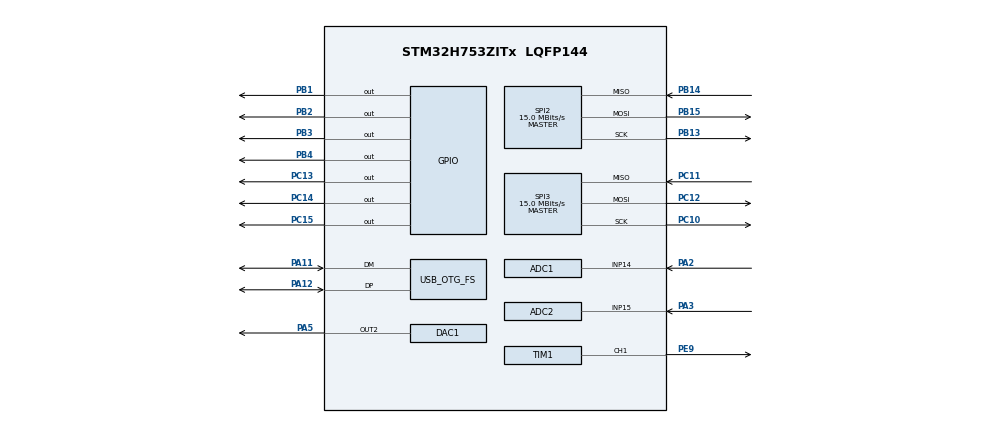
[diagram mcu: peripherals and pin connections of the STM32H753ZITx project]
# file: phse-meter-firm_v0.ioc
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ADC1.Channel-0\#ChannelRegularConversion=ADC_CHANNEL_14
ADC1.ConversionDataManagement=ADC_CONVERSIONDATA_DMA_CIRCULAR
ADC1.ExternalTrigConv=ADC_EXTERNALTRIG_T1_TRGO
ADC1.Mode=ADC_DUALMODE_REGSIMULT
ADC1.NbrOfConversionFlag=1
ADC1.OffsetNumber-0\#ChannelRegularConversion=ADC_OFFSET_NONE
ADC1.OffsetSignedSaturation-0\#ChannelRegularConversion=DISABLE
ADC1.Rank-0\#ChannelRegularConversion=1
ADC1.Resolution=ADC_RESOLUTION_16B
ADC1.SamplingTime-0\#ChannelRegularConversion=ADC_SAMPLETIME_8CYCLES_5
ADC1.master=1
ADC2.Channel-0\#ChannelRegularConversion=ADC_CHANNEL_15
ADC2.ClockPrescaler=ADC_CLOCK_ASYNC_DIV1
ADC2.Mode=ADC_DUALMODE_REGSIMULT
ADC2.NbrOfConversionFlag=1
ADC2.OffsetNumber-0\#ChannelRegularConversion=ADC_OFFSET_NONE
ADC2.OffsetSignedSaturation-0\#ChannelRegularConversion=DISABLE
ADC2.Rank-0\#ChannelRegularConversion=1
ADC2.Resolution=ADC_RESOLUTION_16B
ADC2.SamplingTime-0\#ChannelRegularConversion=ADC_SAMPLETIME_8CYCLES_5
CORTEX_M7.CPU_DCache=Disabled
CORTEX_M7.CPU_ICache=Disabled
CORTEX_M7.MPU_Control=__NULL
CORTEX_M7.default_mode_Activation=1
DAC1.DAC_Channel-DAC_OUT2=DAC_CHANNEL_2
Dma.ADC1.0.Direction=DMA_PERIPH_TO_MEMORY
Dma.ADC1.0.EventEnable=DISABLE
Dma.ADC1.0.FIFOMode=DMA_FIFOMODE_DISABLE
Dma.ADC1.0.Instance=DMA1_Stream0
Dma.ADC1.0.MemDataAlignment=DMA_MDATAALIGN_WORD
Dma.ADC1.0.MemInc=DMA_MINC_ENABLE
Dma.ADC1.0.Mode=DMA_CIRCULAR
Dma.ADC1.0.PeriphDataAlignment=DMA_PDATAALIGN_WORD
Dma.ADC1.0.PeriphInc=DMA_PINC_DISABLE
Dma.ADC1.0.Polarity=HAL_DMAMUX_REQ_GEN_RISING
Dma.ADC1.0.Priority=DMA_PRIORITY_LOW
Dma.ADC1.0.RequestNumber=1
Dma.ADC1.0.SignalID=NONE
Dma.ADC1.0.SyncEnable=DISABLE
Dma.ADC1.0.SyncPolarity=HAL_DMAMUX_SYNC_NO_EVENT
Dma.ADC1.0.SyncRequestNumber=1
Dma.ADC1.0.SyncSignalID=NONE
Dma.Request0=ADC1
Mcu.Family=STM32H7
Mcu.Name=STM32H753ZITx
Mcu.Package=LQFP144
NUCLEO-H753ZI.VCP=true
NVIC.DMA1_Stream0_IRQn=true\:0\:0\:false\:false\:true\:false\:true\:true
NVIC.OTG_FS_IRQn=true\:0\:0\:false\:false\:true\:false\:true\:true
NVIC.PriorityGroup=NVIC_PRIORITYGROUP_4
NVIC.TIM6_DAC_IRQn=true\:0\:0\:false\:false\:true\:true\:true\:true
PA11.Mode=Device_Only
PA11.Signal=USB_OTG_FS_DM
PA12.Mode=Device_Only
PA12.Signal=USB_OTG_FS_DP
PA2.Signal=ADCx_INP14
PA3.Signal=ADCx_INP15
PA5.Signal=COMP_DAC12_group
PB1.Signal=GPIO_Output
PB13.Mode=Full_Duplex_Master
PB13.Signal=SPI2_SCK
PB14.Mode=Full_Duplex_Master
PB14.Signal=SPI2_MISO
PB15.Mode=Full_Duplex_Master
PB15.Signal=SPI2_MOSI
PB2.Signal=GPIO_Output
PB3\ (JTDO/TRACESWO).Signal=GPIO_Output
PB4\ (NJTRST).Signal=GPIO_Output
PC10.Mode=Full_Duplex_Master
PC10.Signal=SPI3_SCK
PC11.Mode=Full_Duplex_Master
PC11.Signal=SPI3_MISO
PC12.Mode=Full_Duplex_Master
PC12.Signal=SPI3_MOSI
PC13.Signal=GPIO_Output
PC14-OSC32_IN\ (OSC32_IN).Signal=GPIO_Output
PC15-OSC32_OUT\ (OSC32_OUT).Signal=GPIO_Output
PD8.Signal=USART3_TX
PD9.Signal=USART3_RX
PE7.Signal=S_TIM1_ETR
PE9.Signal=S_TIM1_CH1
PH0-OSC_IN\ (PH0).Mode=HSE-External-Oscillator
PH0-OSC_IN\ (PH0).Signal=RCC_OSC_IN
PH1-OSC_OUT\ (PH1).Mode=HSE-External-Oscillator
PH1-OSC_OUT\ (PH1).Signal=RCC_OSC_OUT
ProjectManager.HeapSize=0x200
ProjectManager.StackSize=0x400
ProjectManager.TargetToolchain=STM32CubeIDE
RCC.ADCFreq_Value=50000000
RCC.APB1Freq_Value=120000000
RCC.APB2Freq_Value=120000000
RCC.APB3Freq_Value=120000000
RCC.APB4Freq_Value=120000000
RCC.CortexFreq_Value=480000000
RCC.D1PPRE=RCC_APB3_DIV2
RCC.D2PPRE1=RCC_APB1_DIV2
RCC.D2PPRE2=RCC_APB2_DIV2
RCC.D3PPRE=RCC_APB4_DIV2
RCC.DIVM1=2
RCC.DIVM2=2
RCC.DIVN1=240
RCC.DIVN2=50
RCC.DIVP2=4
RCC.DIVQ1=8
RCC.HCLKFreq_Value=240000000
RCC.HPRE=RCC_HCLK_DIV2
RCC.HSE_VALUE=8000000
RCC.PLL2FRACN=0
RCC.PLLFRACN=0
RCC.PLLSourceVirtual=RCC_PLLSOURCE_HSE
RCC.PWR_Regulator_Voltage_Scale=PWR_REGULATOR_VOLTAGE_SCALE0
RCC.SYSCLKFreq_VALUE=480000000
RCC.SYSCLKSource=RCC_SYSCLKSOURCE_PLLCLK
RCC.USBCLockSelection=RCC_USBCLKSOURCE_HSI48
RCC.USBFreq_Value=48000000
SH.ADCx_INP14.0=ADC1_INP14,IN14-Single-Ended
SH.ADCx_INP15.0=ADC2_INP15,IN15-Single-Ended
SH.COMP_DAC12_group.0=DAC1_OUT2,DAC_OUT2
SH.S_TIM1_CH1.0=TIM1_CH1,PWM Generation1 CH1
SH.S_TIM1_ETR.0=TIM1_ETR
SPI2.BaudRatePrescaler=SPI_BAUDRATEPRESCALER_8
SPI2.CalculateBaudRate=15.0 MBits/s
SPI2.DataSize=SPI_DATASIZE_8BIT
SPI2.Direction=SPI_DIRECTION_2LINES
SPI2.FirstBit=SPI_FIRSTBIT_LSB
SPI2.Mode=SPI_MODE_MASTER
SPI2.VirtualType=VM_MASTER
SPI3.BaudRatePrescaler=SPI_BAUDRATEPRESCALER_8
SPI3.CalculateBaudRate=15.0 MBits/s
SPI3.DataSize=SPI_DATASIZE_8BIT
SPI3.Direction=SPI_DIRECTION_2LINES
SPI3.FirstBit=SPI_FIRSTBIT_LSB
SPI3.Mode=SPI_MODE_MASTER
SPI3.VirtualType=VM_MASTER
TIM1.Channel-PWM\ Generation1\ CH1=TIM_CHANNEL_1
TIM1.Period=240-1
TIM1.Pulse-PWM\ Generation1\ CH1=120
TIM1.TIM_MasterOutputTrigger=TIM_TRGO_UPDATE
TIM6.Period=1000-1
TIM6.Prescaler=2400-1
USB_DEVICE.CLASS_NAME_FS=CDC
USB_DEVICE.VirtualMode-CDC_FS=Cdc
USB_DEVICE.VirtualModeFS=Cdc_FS
USB_OTG_FS.VirtualMode=Device_Only
VP_MEMORYMAP_VS_MEMORYMAP.Mode=CurAppReg
VP_NUCLEO-H753ZI_VS_BSP_COMMON.Mode=COMMON
VP_TIM1_VS_ClockSourceINT.Mode=Internal
VP_TIM6_VS_ClockSourceINT.Mode=Enable_Timer
VP_USB_DEVICE_VS_USB_DEVICE_CDC_FS.Mode=CDC_FS
board=NUCLEO-H753ZI

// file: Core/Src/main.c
/* USER CODE BEGIN Header */
/**
  ******************************************************************************
  * @file           : main.c
  * @brief          : Main program body
  ******************************************************************************
  * @attention
  *
  * Copyright (c) 2026 STMicroelectronics.
  * All rights reserved.
  *
  * This software is licensed under terms that can be found in the LICENSE file
  * in the root directory of this software component.
  * If no LICENSE file comes with this software, it is provided AS-IS.
  *
  ******************************************************************************
  */
/* USER CODE END Header */
#include "main.h"
#include "usb_device.h"

/* USER CODE BEGIN Includes */
#include "functions.h"
/* USER CODE END Includes */

COM_InitTypeDef BspCOMInit;
ADC_HandleTypeDef hadc1;
ADC_HandleTypeDef hadc2;
DMA_HandleTypeDef hdma_adc1;

DAC_HandleTypeDef hdac1;

SPI_HandleTypeDef hspi2;
SPI_HandleTypeDef hspi3;

TIM_HandleTypeDef htim1;
TIM_HandleTypeDef htim6;

void SystemClock_Config(void);
void PeriphCommonClock_Config(void);
static void MX_GPIO_Init(void);
static void MX_DMA_Init(void);
static void MX_ADC1_Init(void);
static void MX_ADC2_Init(void);
static void MX_TIM1_Init(void);
static void MX_TIM6_Init(void);
static void MX_SPI2_Init(void);
static void MX_SPI3_Init(void);
static void MX_DAC1_Init(void);

int main(void)
{

  /* MCU Configuration--------------------------------------------------------*/

  /* Reset of all peripherals, Initializes the Flash interface and the Systick. */
  HAL_Init();

  /* Configure the system clock */
  SystemClock_Config();

  /* Configure the peripherals common clocks */
  PeriphCommonClock_Config();

  /* Initialize all configured peripherals */
  MX_GPIO_Init();
  MX_DMA_Init();
  MX_ADC1_Init();
  MX_ADC2_Init();
  MX_USB_DEVICE_Init();
  MX_TIM1_Init();
  MX_TIM6_Init();
  MX_SPI2_Init();
  MX_SPI3_Init();
  MX_DAC1_Init();
  /* USER CODE BEGIN 2 */
  StartUp();      /* clocks, params, ADC multimode/calib, TIM1 trigger */
  Start_Main();   /* enable the 100 Hz TIM6 tick                       */
  /* USER CODE END 2 */

  /* Initialize COM1 port (115200, 8 bits (7-bit data + 1 stop bit), no parity */
  BspCOMInit.BaudRate   = 115200;
  BspCOMInit.WordLength = COM_WORDLENGTH_8B;
  BspCOMInit.StopBits   = COM_STOPBITS_1;
  BspCOMInit.Parity     = COM_PARITY_NONE;
  BspCOMInit.HwFlowCtl  = COM_HWCONTROL_NONE;
  if (BSP_COM_Init(COM1, &BspCOMInit) != BSP_ERROR_NONE)
  {
    Error_Handler();
  }

  /* Infinite loop */
  while (1)
  {

    /* USER CODE BEGIN 3 */
    Main_Processing();
  }
  /* USER CODE END 3 */
}

void SystemClock_Config(void)
{
  RCC_OscInitTypeDef RCC_OscInitStruct = {0};
  RCC_ClkInitTypeDef RCC_ClkInitStruct = {0};

  /** Supply configuration update enable
  */
  HAL_PWREx_ConfigSupply(PWR_LDO_SUPPLY);

  /** Configure the main internal regulator output voltage
  */
  __HAL_PWR_VOLTAGESCALING_CONFIG(PWR_REGULATOR_VOLTAGE_SCALE0);

  while(!__HAL_PWR_GET_FLAG(PWR_FLAG_VOSRDY)) {}

  /** Initializes the RCC Oscillators according to the specified parameters
  * in the RCC_OscInitTypeDef structure.
  */
  RCC_OscInitStruct.OscillatorType = RCC_OSCILLATORTYPE_HSI48|RCC_OSCILLATORTYPE_HSE;
  RCC_OscInitStruct.HSEState = RCC_HSE_ON;
  RCC_OscInitStruct.HSI48State = RCC_HSI48_ON;
  RCC_OscInitStruct.PLL.PLLState = RCC_PLL_ON;
  RCC_OscInitStruct.PLL.PLLSource = RCC_PLLSOURCE_HSE;
  RCC_OscInitStruct.PLL.PLLM = 2;
  RCC_OscInitStruct.PLL.PLLN = 240;
  RCC_OscInitStruct.PLL.PLLP = 2;
  RCC_OscInitStruct.PLL.PLLQ = 8;
  RCC_OscInitStruct.PLL.PLLR = 2;
  RCC_OscInitStruct.PLL.PLLRGE = RCC_PLL1VCIRANGE_2;
  RCC_OscInitStruct.PLL.PLLVCOSEL = RCC_PLL1VCOWIDE;
  RCC_OscInitStruct.PLL.PLLFRACN = 0;
  if (HAL_RCC_OscConfig(&RCC_OscInitStruct) != HAL_OK)
  {
    Error_Handler();
  }

  /** Initializes the CPU, AHB and APB buses clocks
  */
  RCC_ClkInitStruct.ClockType = RCC_CLOCKTYPE_HCLK|RCC_CLOCKTYPE_SYSCLK
                              |RCC_CLOCKTYPE_PCLK1|RCC_CLOCKTYPE_PCLK2
                              |RCC_CLOCKTYPE_D3PCLK1|RCC_CLOCKTYPE_D1PCLK1;
  RCC_ClkInitStruct.SYSCLKSource = RCC_SYSCLKSOURCE_PLLCLK;
  RCC_ClkInitStruct.SYSCLKDivider = RCC_SYSCLK_DIV1;
  RCC_ClkInitStruct.AHBCLKDivider = RCC_HCLK_DIV2;
  RCC_ClkInitStruct.APB3CLKDivider = RCC_APB3_DIV2;
  RCC_ClkInitStruct.APB1CLKDivider = RCC_APB1_DIV2;
  RCC_ClkInitStruct.APB2CLKDivider = RCC_APB2_DIV2;
  RCC_ClkInitStruct.APB4CLKDivider = RCC_APB4_DIV2;

  if (HAL_RCC_ClockConfig(&RCC_ClkInitStruct, FLASH_LATENCY_4) != HAL_OK)
  {
    Error_Handler();
  }
}

void PeriphCommonClock_Config(void)
{
  RCC_PeriphCLKInitTypeDef PeriphClkInitStruct = {0};

  /** Initializes the peripherals clock
  */
  PeriphClkInitStruct.PeriphClockSelection = RCC_PERIPHCLK_ADC;
  PeriphClkInitStruct.PLL2.PLL2M = 2;
  PeriphClkInitStruct.PLL2.PLL2N = 50;
  PeriphClkInitStruct.PLL2.PLL2P = 4;
  PeriphClkInitStruct.PLL2.PLL2Q = 2;
  PeriphClkInitStruct.PLL2.PLL2R = 2;
  PeriphClkInitStruct.PLL2.PLL2RGE = RCC_PLL2VCIRANGE_2;
  PeriphClkInitStruct.PLL2.PLL2VCOSEL = RCC_PLL2VCOWIDE;
  PeriphClkInitStruct.PLL2.PLL2FRACN = 0;
  PeriphClkInitStruct.AdcClockSelection = RCC_ADCCLKSOURCE_PLL2;
  if (HAL_RCCEx_PeriphCLKConfig(&PeriphClkInitStruct) != HAL_OK)
  {
    Error_Handler();
  }
}

static void MX_ADC1_Init(void)
{

  ADC_MultiModeTypeDef multimode = {0};
  ADC_ChannelConfTypeDef sConfig = {0};

  /** Common config
  */
  hadc1.Instance = ADC1;
  hadc1.Init.ClockPrescaler = ADC_CLOCK_ASYNC_DIV1;
  hadc1.Init.Resolution = ADC_RESOLUTION_16B;
  hadc1.Init.ScanConvMode = ADC_SCAN_DISABLE;
  hadc1.Init.EOCSelection = ADC_EOC_SINGLE_CONV;
  hadc1.Init.LowPowerAutoWait = DISABLE;
  hadc1.Init.ContinuousConvMode = DISABLE;
  hadc1.Init.NbrOfConversion = 1;
  hadc1.Init.DiscontinuousConvMode = DISABLE;
  hadc1.Init.ExternalTrigConv = ADC_EXTERNALTRIG_T1_TRGO;
  hadc1.Init.ExternalTrigConvEdge = ADC_EXTERNALTRIGCONVEDGE_RISING;
  hadc1.Init.ConversionDataManagement = ADC_CONVERSIONDATA_DMA_CIRCULAR;
  hadc1.Init.Overrun = ADC_OVR_DATA_PRESERVED;
  hadc1.Init.LeftBitShift = ADC_LEFTBITSHIFT_NONE;
  hadc1.Init.OversamplingMode = DISABLE;
  hadc1.Init.Oversampling.Ratio = 1;
  if (HAL_ADC_Init(&hadc1) != HAL_OK)
  {
    Error_Handler();
  }

  /** Configure the ADC multi-mode
  */
  multimode.Mode = ADC_DUALMODE_REGSIMULT;
  multimode.DualModeData = ADC_DUALMODEDATAFORMAT_DISABLED;
  multimode.TwoSamplingDelay = ADC_TWOSAMPLINGDELAY_1CYCLE;
  if (HAL_ADCEx_MultiModeConfigChannel(&hadc1, &multimode) != HAL_OK)
  {
    Error_Handler();
  }

  /** Configure Regular Channel
  */
  sConfig.Channel = ADC_CHANNEL_14;
  sConfig.Rank = ADC_REGULAR_RANK_1;
  sConfig.SamplingTime = ADC_SAMPLETIME_8CYCLES_5;
  sConfig.SingleDiff = ADC_SINGLE_ENDED;
  sConfig.OffsetNumber = ADC_OFFSET_NONE;
  sConfig.Offset = 0;
  sConfig.OffsetSignedSaturation = DISABLE;
  if (HAL_ADC_ConfigChannel(&hadc1, &sConfig) != HAL_OK)
  {
    Error_Handler();
  }

}

static void MX_ADC2_Init(void)
{

  ADC_ChannelConfTypeDef sConfig = {0};

  /** Common config
  */
  hadc2.Instance = ADC2;
  hadc2.Init.ClockPrescaler = ADC_CLOCK_ASYNC_DIV1;
  hadc2.Init.Resolution = ADC_RESOLUTION_16B;
  hadc2.Init.ScanConvMode = ADC_SCAN_DISABLE;
  hadc2.Init.EOCSelection = ADC_EOC_SINGLE_CONV;
  hadc2.Init.LowPowerAutoWait = DISABLE;
  hadc2.Init.ContinuousConvMode = DISABLE;
  hadc2.Init.NbrOfConversion = 1;
  hadc2.Init.DiscontinuousConvMode = DISABLE;
  hadc2.Init.ConversionDataManagement = ADC_CONVERSIONDATA_DR;
  hadc2.Init.Overrun = ADC_OVR_DATA_PRESERVED;
  hadc2.Init.LeftBitShift = ADC_LEFTBITSHIFT_NONE;
  hadc2.Init.OversamplingMode = DISABLE;
  hadc2.Init.Oversampling.Ratio = 1;
  if (HAL_ADC_Init(&hadc2) != HAL_OK)
  {
    Error_Handler();
  }

  /** Configure Regular Channel
  */
  sConfig.Channel = ADC_CHANNEL_15;
  sConfig.Rank = ADC_REGULAR_RANK_1;
  sConfig.SamplingTime = ADC_SAMPLETIME_8CYCLES_5;
  sConfig.SingleDiff = ADC_SINGLE_ENDED;
  sConfig.OffsetNumber = ADC_OFFSET_NONE;
  sConfig.Offset = 0;
  sConfig.OffsetSignedSaturation = DISABLE;
  if (HAL_ADC_ConfigChannel(&hadc2, &sConfig) != HAL_OK)
  {
    Error_Handler();
  }

}

static void MX_DAC1_Init(void)
{

  DAC_ChannelConfTypeDef sConfig = {0};

  /** DAC Initialization
  */
  hdac1.Instance = DAC1;
  if (HAL_DAC_Init(&hdac1) != HAL_OK)
  {
    Error_Handler();
  }

  /** DAC channel OUT2 config
  */
  sConfig.DAC_SampleAndHold = DAC_SAMPLEANDHOLD_DISABLE;
  sConfig.DAC_Trigger = DAC_TRIGGER_NONE;
  sConfig.DAC_OutputBuffer = DAC_OUTPUTBUFFER_ENABLE;
  sConfig.DAC_ConnectOnChipPeripheral = DAC_CHIPCONNECT_DISABLE;
  sConfig.DAC_UserTrimming = DAC_TRIMMING_FACTORY;
  if (HAL_DAC_ConfigChannel(&hdac1, &sConfig, DAC_CHANNEL_2) != HAL_OK)
  {
    Error_Handler();
  }

}

static void MX_SPI2_Init(void)
{

  /* SPI2 parameter configuration*/
  hspi2.Instance = SPI2;
  hspi2.Init.Mode = SPI_MODE_MASTER;
  hspi2.Init.Direction = SPI_DIRECTION_2LINES;
  hspi2.Init.DataSize = SPI_DATASIZE_8BIT;
  hspi2.Init.CLKPolarity = SPI_POLARITY_LOW;
  hspi2.Init.CLKPhase = SPI_PHASE_1EDGE;
  hspi2.Init.NSS = SPI_NSS_SOFT;
  hspi2.Init.BaudRatePrescaler = SPI_BAUDRATEPRESCALER_8;
  hspi2.Init.FirstBit = SPI_FIRSTBIT_LSB;
  hspi2.Init.TIMode = SPI_TIMODE_DISABLE;
  hspi2.Init.CRCCalculation = SPI_CRCCALCULATION_DISABLE;
  hspi2.Init.CRCPolynomial = 0x0;
  hspi2.Init.NSSPMode = SPI_NSS_PULSE_ENABLE;
  hspi2.Init.NSSPolarity = SPI_NSS_POLARITY_LOW;
  hspi2.Init.FifoThreshold = SPI_FIFO_THRESHOLD_01DATA;
  hspi2.Init.TxCRCInitializationPattern = SPI_CRC_INITIALIZATION_ALL_ZERO_PATTERN;
  hspi2.Init.RxCRCInitializationPattern = SPI_CRC_INITIALIZATION_ALL_ZERO_PATTERN;
  hspi2.Init.MasterSSIdleness = SPI_MASTER_SS_IDLENESS_00CYCLE;
  hspi2.Init.MasterInterDataIdleness = SPI_MASTER_INTERDATA_IDLENESS_00CYCLE;
  hspi2.Init.MasterReceiverAutoSusp = SPI_MASTER_RX_AUTOSUSP_DISABLE;
  hspi2.Init.MasterKeepIOState = SPI_MASTER_KEEP_IO_STATE_DISABLE;
  hspi2.Init.IOSwap = SPI_IO_SWAP_DISABLE;
  if (HAL_SPI_Init(&hspi2) != HAL_OK)
  {
    Error_Handler();
  }

}

static void MX_SPI3_Init(void)
{

  /* SPI3 parameter configuration*/
  hspi3.Instance = SPI3;
  hspi3.Init.Mode = SPI_MODE_MASTER;
  hspi3.Init.Direction = SPI_DIRECTION_2LINES;
  hspi3.Init.DataSize = SPI_DATASIZE_8BIT;
  hspi3.Init.CLKPolarity = SPI_POLARITY_LOW;
  hspi3.Init.CLKPhase = SPI_PHASE_1EDGE;
  hspi3.Init.NSS = SPI_NSS_SOFT;
  hspi3.Init.BaudRatePrescaler = SPI_BAUDRATEPRESCALER_8;
  hspi3.Init.FirstBit = SPI_FIRSTBIT_LSB;
  hspi3.Init.TIMode = SPI_TIMODE_DISABLE;
  hspi3.Init.CRCCalculation = SPI_CRCCALCULATION_DISABLE;
  hspi3.Init.CRCPolynomial = 0x0;
  hspi3.Init.NSSPMode = SPI_NSS_PULSE_ENABLE;
  hspi3.Init.NSSPolarity = SPI_NSS_POLARITY_LOW;
  hspi3.Init.FifoThreshold = SPI_FIFO_THRESHOLD_01DATA;
  hspi3.Init.TxCRCInitializationPattern = SPI_CRC_INITIALIZATION_ALL_ZERO_PATTERN;
  hspi3.Init.RxCRCInitializationPattern = SPI_CRC_INITIALIZATION_ALL_ZERO_PATTERN;
  hspi3.Init.MasterSSIdleness = SPI_MASTER_SS_IDLENESS_00CYCLE;
  hspi3.Init.MasterInterDataIdleness = SPI_MASTER_INTERDATA_IDLENESS_00CYCLE;
  hspi3.Init.MasterReceiverAutoSusp = SPI_MASTER_RX_AUTOSUSP_DISABLE;
  hspi3.Init.MasterKeepIOState = SPI_MASTER_KEEP_IO_STATE_DISABLE;
  hspi3.Init.IOSwap = SPI_IO_SWAP_DISABLE;
  if (HAL_SPI_Init(&hspi3) != HAL_OK)
  {
    Error_Handler();
  }

}

static void MX_TIM1_Init(void)
{

  TIM_ClockConfigTypeDef sClockSourceConfig = {0};
  TIM_MasterConfigTypeDef sMasterConfig = {0};
  TIM_OC_InitTypeDef sConfigOC = {0};
  TIM_BreakDeadTimeConfigTypeDef sBreakDeadTimeConfig = {0};

  htim1.Instance = TIM1;
  htim1.Init.Prescaler = 0;
  htim1.Init.CounterMode = TIM_COUNTERMODE_UP;
  htim1.Init.Period = 240-1;
  htim1.Init.ClockDivision = TIM_CLOCKDIVISION_DIV1;
  htim1.Init.RepetitionCounter = 0;
  htim1.Init.AutoReloadPreload = TIM_AUTORELOAD_PRELOAD_DISABLE;
  if (HAL_TIM_Base_Init(&htim1) != HAL_OK)
  {
    Error_Handler();
  }
  sClockSourceConfig.ClockSource = TIM_CLOCKSOURCE_INTERNAL;
  if (HAL_TIM_ConfigClockSource(&htim1, &sClockSourceConfig) != HAL_OK)
  {
    Error_Handler();
  }
  if (HAL_TIM_PWM_Init(&htim1) != HAL_OK)
  {
    Error_Handler();
  }
  sMasterConfig.MasterOutputTrigger = TIM_TRGO_UPDATE;
  sMasterConfig.MasterOutputTrigger2 = TIM_TRGO2_RESET;
  sMasterConfig.MasterSlaveMode = TIM_MASTERSLAVEMODE_DISABLE;
  if (HAL_TIMEx_MasterConfigSynchronization(&htim1, &sMasterConfig) != HAL_OK)
  {
    Error_Handler();
  }
  sConfigOC.OCMode = TIM_OCMODE_PWM1;
  sConfigOC.Pulse = 120;
  sConfigOC.OCPolarity = TIM_OCPOLARITY_HIGH;
  sConfigOC.OCNPolarity = TIM_OCNPOLARITY_HIGH;
  sConfigOC.OCFastMode = TIM_OCFAST_DISABLE;
  sConfigOC.OCIdleState = TIM_OCIDLESTATE_RESET;
  sConfigOC.OCNIdleState = TIM_OCNIDLESTATE_RESET;
  if (HAL_TIM_PWM_ConfigChannel(&htim1, &sConfigOC, TIM_CHANNEL_1) != HAL_OK)
  {
    Error_Handler();
  }
  sBreakDeadTimeConfig.OffStateRunMode = TIM_OSSR_DISABLE;
  sBreakDeadTimeConfig.OffStateIDLEMode = TIM_OSSI_DISABLE;
  sBreakDeadTimeConfig.LockLevel = TIM_LOCKLEVEL_OFF;
  sBreakDeadTimeConfig.DeadTime = 0;
  sBreakDeadTimeConfig.BreakState = TIM_BREAK_DISABLE;
  sBreakDeadTimeConfig.BreakPolarity = TIM_BREAKPOLARITY_HIGH;
  sBreakDeadTimeConfig.BreakFilter = 0;
  sBreakDeadTimeConfig.Break2State = TIM_BREAK2_DISABLE;
  sBreakDeadTimeConfig.Break2Polarity = TIM_BREAK2POLARITY_HIGH;
  sBreakDeadTimeConfig.Break2Filter = 0;
  sBreakDeadTimeConfig.AutomaticOutput = TIM_AUTOMATICOUTPUT_DISABLE;
  if (HAL_TIMEx_ConfigBreakDeadTime(&htim1, &sBreakDeadTimeConfig) != HAL_OK)
  {
    Error_Handler();
  }
  HAL_TIM_MspPostInit(&htim1);

}

static void MX_TIM6_Init(void)
{

  TIM_MasterConfigTypeDef sMasterConfig = {0};

  htim6.Instance = TIM6;
  htim6.Init.Prescaler = 2400-1;
  htim6.Init.CounterMode = TIM_COUNTERMODE_UP;
  htim6.Init.Period = 1000-1;
  htim6.Init.AutoReloadPreload = TIM_AUTORELOAD_PRELOAD_DISABLE;
  if (HAL_TIM_Base_Init(&htim6) != HAL_OK)
  {
    Error_Handler();
  }
  sMasterConfig.MasterOutputTrigger = TIM_TRGO_RESET;
  sMasterConfig.MasterSlaveMode = TIM_MASTERSLAVEMODE_DISABLE;
  if (HAL_TIMEx_MasterConfigSynchronization(&htim6, &sMasterConfig) != HAL_OK)
  {
    Error_Handler();
  }

}

static void MX_DMA_Init(void)
{

  /* DMA controller clock enable */
  __HAL_RCC_DMA1_CLK_ENABLE();

  /* DMA interrupt init */
  /* DMA1_Stream0_IRQn interrupt configuration */
  HAL_NVIC_SetPriority(DMA1_Stream0_IRQn, 0, 0);
  HAL_NVIC_EnableIRQ(DMA1_Stream0_IRQn);

}

static void MX_GPIO_Init(void)
{
  GPIO_InitTypeDef GPIO_InitStruct = {0};

  /* GPIO Ports Clock Enable */
  __HAL_RCC_GPIOC_CLK_ENABLE();
  __HAL_RCC_GPIOH_CLK_ENABLE();
  __HAL_RCC_GPIOA_CLK_ENABLE();
  __HAL_RCC_GPIOB_CLK_ENABLE();
  __HAL_RCC_GPIOE_CLK_ENABLE();

  /*Configure GPIO pin Output Level */
  HAL_GPIO_WritePin(GPIOC, GPIO_PIN_13|GPIO_PIN_14|GPIO_PIN_15, GPIO_PIN_RESET);

  /*Configure GPIO pin Output Level */
  HAL_GPIO_WritePin(GPIOB, GPIO_PIN_1|GPIO_PIN_2|GPIO_PIN_3|GPIO_PIN_4, GPIO_PIN_RESET);

  /*Configure GPIO pins : PC13 PC14 PC15 */
  GPIO_InitStruct.Pin = GPIO_PIN_13|GPIO_PIN_14|GPIO_PIN_15;
  GPIO_InitStruct.Mode = GPIO_MODE_OUTPUT_PP;
  GPIO_InitStruct.Pull = GPIO_NOPULL;
  GPIO_InitStruct.Speed = GPIO_SPEED_FREQ_LOW;
  HAL_GPIO_Init(GPIOC, &GPIO_InitStruct);

  /*Configure GPIO pins : PB1 PB2 PB3 PB4 */
  GPIO_InitStruct.Pin = GPIO_PIN_1|GPIO_PIN_2|GPIO_PIN_3|GPIO_PIN_4;
  GPIO_InitStruct.Mode = GPIO_MODE_OUTPUT_PP;
  GPIO_InitStruct.Pull = GPIO_NOPULL;
  GPIO_InitStruct.Speed = GPIO_SPEED_FREQ_LOW;
  HAL_GPIO_Init(GPIOB, &GPIO_InitStruct);

}

void Error_Handler(void)
{
  __disable_irq();
  while (1)
  {
  }
}
